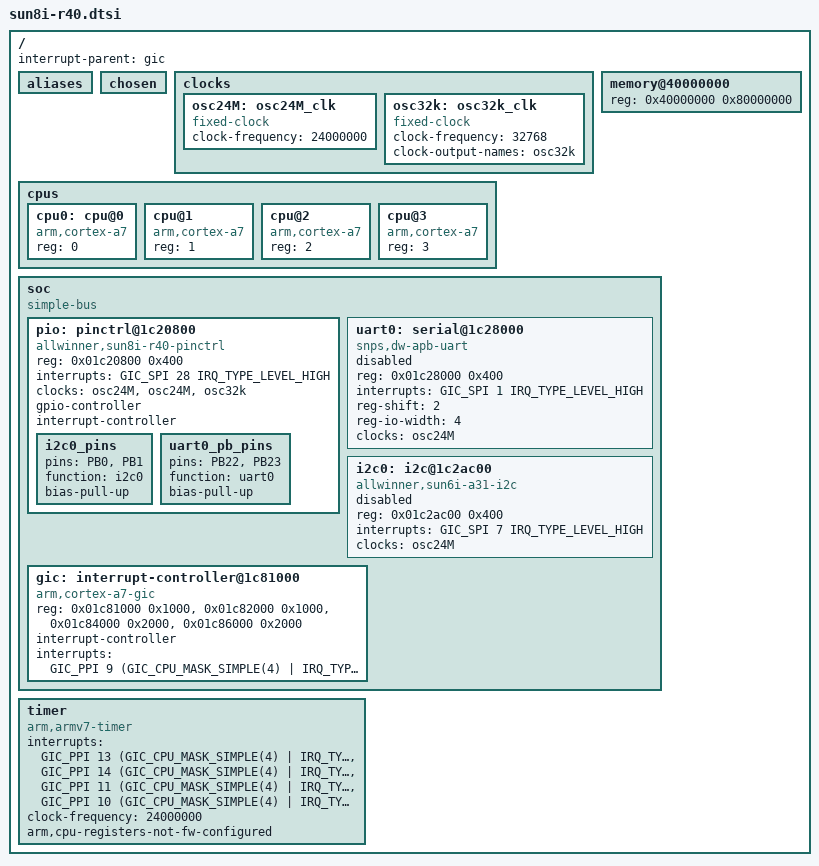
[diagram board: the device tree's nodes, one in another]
/*
 * Copyright 2016 Chen-Yu Tsai
 *
 * Chen-Yu Tsai <wens@csie.org>
 *
 * This file is dual-licensed: you can use it either under the terms
 * of the GPL or the X11 license, at your option. Note that this dual
 * licensing only applies to this file, and not this project as a
 * whole.
 *
 *  a) This file is free software; you can redistribute it and/or
 *     modify it under the terms of the GNU General Public License as
 *     published by the Free Software Foundation; either version 2 of the
 *     License, or (at your option) any later version.
 *
 *     This file is distributed in the hope that it will be useful,
 *     but WITHOUT ANY WARRANTY; without even the implied warranty of
 *     MERCHANTABILITY or FITNESS FOR A PARTICULAR PURPOSE.  See the
 *     GNU General Public License for more details.
 *
 * Or, alternatively,
 *
 *  b) Permission is hereby granted, free of charge, to any person
 *     obtaining a copy of this software and associated documentation
 *     files (the "Software"), to deal in the Software without
 *     restriction, including without limitation the rights to use,
 *     copy, modify, merge, publish, distribute, sublicense, and/or
 *     sell copies of the Software, and to permit persons to whom the
 *     Software is furnished to do so, subject to the following
 *     conditions:
 *
 *     The above copyright notice and this permission notice shall be
 *     included in all copies or substantial portions of the Software.
 *
 *     THE SOFTWARE IS PROVIDED "AS IS", WITHOUT WARRANTY OF ANY KIND,
 *     EXPRESS OR IMPLIED, INCLUDING BUT NOT LIMITED TO THE WARRANTIES
 *     OF MERCHANTABILITY, FITNESS FOR A PARTICULAR PURPOSE AND
 *     NONINFRINGEMENT. IN NO EVENT SHALL THE AUTHORS OR COPYRIGHT
 *     HOLDERS BE LIABLE FOR ANY CLAIM, DAMAGES OR OTHER LIABILITY,
 *     WHETHER IN AN ACTION OF CONTRACT, TORT OR OTHERWISE, ARISING
 *     FROM, OUT OF OR IN CONNECTION WITH THE SOFTWARE OR THE USE OR
 *     OTHER DEALINGS IN THE SOFTWARE.
 */

#include <dt-bindings/interrupt-controller/arm-gic.h>

/ {
	#address-cells = <1>;
	#size-cells = <1>;
	interrupt-parent = <&gic>;

	aliases {
	};

	chosen {
	};

	clocks {
		#address-cells = <1>;
		#size-cells = <1>;
		ranges;

		osc24M: osc24M_clk {
			#clock-cells = <0>;
			compatible = "fixed-clock";
			clock-frequency = <24000000>;
		};

		osc32k: osc32k_clk {
			#clock-cells = <0>;
			compatible = "fixed-clock";
			clock-frequency = <32768>;
			clock-output-names = "osc32k";
		};
	};

	cpus {
		#address-cells = <1>;
		#size-cells = <0>;

		cpu0: cpu@0 {
			compatible = "arm,cortex-a7";
			device_type = "cpu";
			reg = <0>;
		};

		cpu@1 {
			compatible = "arm,cortex-a7";
			device_type = "cpu";
			reg = <1>;
		};

		cpu@2 {
			compatible = "arm,cortex-a7";
			device_type = "cpu";
			reg = <2>;
		};

		cpu@3 {
			compatible = "arm,cortex-a7";
			device_type = "cpu";
			reg = <3>;
		};
	};

	memory@40000000 {
		device_type = "memory";
		reg = <0x40000000 0x80000000>;
	};

	soc {
		compatible = "simple-bus";
		#address-cells = <1>;
		#size-cells = <1>;
		ranges;

		pio: pinctrl@1c20800 {
			compatible = "allwinner,sun8i-r40-pinctrl";
			reg = <0x01c20800 0x400>;
			interrupts = <GIC_SPI 28 IRQ_TYPE_LEVEL_HIGH>;
			/* apb should be replaced once CCU is implemented */
			clocks = <&osc24M>, <&osc24M>, <&osc32k>;
			clock-names = "apb", "hosc", "losc";
			gpio-controller;
			interrupt-controller;
			#interrupt-cells = <3>;
			#gpio-cells = <3>;

			i2c0_pins: i2c0_pins {
				pins = "PB0", "PB1";
				function = "i2c0";
				bias-pull-up;
			};

			uart0_pb_pins: uart0_pb_pins {
				pins = "PB22", "PB23";
				function = "uart0";
				bias-pull-up;
			};
		};

		uart0: serial@1c28000 {
			compatible = "snps,dw-apb-uart";
			reg = <0x01c28000 0x400>;
			interrupts = <GIC_SPI 1 IRQ_TYPE_LEVEL_HIGH>;
			reg-shift = <2>;
			reg-io-width = <4>;
			clocks = <&osc24M>;
			status = "disabled";
		};

		i2c0: i2c@1c2ac00 {
			compatible = "allwinner,sun6i-a31-i2c";
			reg = <0x01c2ac00 0x400>;
			interrupts = <GIC_SPI 7 IRQ_TYPE_LEVEL_HIGH>;
			clocks = <&osc24M>;
			status = "disabled";
			#address-cells = <1>;
			#size-cells = <0>;
		};

		gic: interrupt-controller@1c81000 {
			compatible = "arm,cortex-a7-gic", "arm,cortex-a15-gic";
			reg = <0x01c81000 0x1000>,
			      <0x01c82000 0x1000>,
			      <0x01c84000 0x2000>,
			      <0x01c86000 0x2000>;
			interrupt-controller;
			#interrupt-cells = <3>;
			interrupts = <GIC_PPI 9 (GIC_CPU_MASK_SIMPLE(4) | IRQ_TYPE_LEVEL_HIGH)>;
		};
	};

	timer {
		compatible = "arm,armv7-timer";
		interrupts = <GIC_PPI 13 (GIC_CPU_MASK_SIMPLE(4) | IRQ_TYPE_LEVEL_LOW)>,
			     <GIC_PPI 14 (GIC_CPU_MASK_SIMPLE(4) | IRQ_TYPE_LEVEL_LOW)>,
			     <GIC_PPI 11 (GIC_CPU_MASK_SIMPLE(4) | IRQ_TYPE_LEVEL_LOW)>,
			     <GIC_PPI 10 (GIC_CPU_MASK_SIMPLE(4) | IRQ_TYPE_LEVEL_LOW)>;
		clock-frequency = <24000000>;
		arm,cpu-registers-not-fw-configured;
	};
};
